# ET6801 register map
Vendor: ETMCU Inc.; File version: v0.0.1
CPU: CM7 r2p1, little endian, MPU, FPU, I-cache, D-cache, ITCM, DTCM, 4 interrupt priority bits
Registers are 32-bit, read-write, reset 0x0 unless marked. A register's access mark holds for its fields unless they carry their own. Offsets are from the block's base; [hi:lo] are bit positions.

## CAN_MISC0 — Provide an overview of the purpose and functionality of the peripheral: mttcan_misc
Base 0x40518800
Same registers: CAN_MISC1 0x40520800, CAN_MISC2 0x40528800
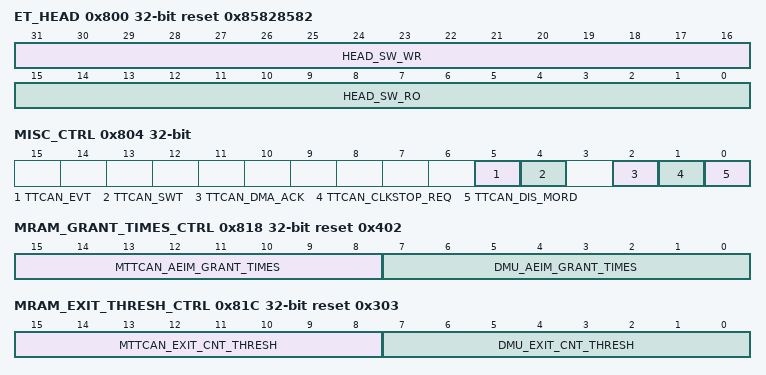
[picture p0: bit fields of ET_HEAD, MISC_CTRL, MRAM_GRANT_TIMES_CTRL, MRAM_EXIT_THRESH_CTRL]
0x800 ET_HEAD reset 0x85828582
  [31:16] HEAD_SW_WR — 软件测试读写寄存器，硬件无访问
  [15:0] HEAD_SW_RO ro — 软件只读上报寄存器，硬件无访问,FDCAN的FC的ASICII 码表示
0x804 MISC_CTRL
  [5] TTCAN_EVT — Event trigger. An edge at this port can directly trigger the transmission of a TTCAN reference message to start a communication cycle when the M_TTCAN is operated in event-synchronized time-triggered mode.
  [4] TTCAN_SWT — Stop-watch trigger An edge at this port can trigger the capturing of one of the M_TTCAN's time bases (local time, cycle time, or global time) into the stopwatch register. This enables the application software to e.g. measure the phase shift between two TTCAN networks.
  [2] TTCAN_DMA_ACK — DMA acknowledge After the transfer of the received messages has completed, the Host activates input signal m_ttcan_dma_ack. This resets m_ttcan_dma_req.
  [1] TTCAN_CLKSTOP_REQ — Clk stop request The M_TTCAN can be set into power down mode controlled by this bit.
  [0] TTCAN_DIS_MORD — Disable modifification on read controls the "disable modifification on read" function. With m_ttcan_dis_mord = '1', resetting of bit fifield ECR.CEL and bits PSR.PXE, PSR.RFDF, PSR.RBRS, PSR.RESI as well as setting of bit fifields PSR.LEC and PSR.DLEC by a read access is disabled. As long as m_ttcan_dis_mord = '1', the CPU can read out these bit fifields repeatedly without resetting/setting them.
0x808 MTTCAN_IR ro
  [31:0] TTCAN_IR — Interrupt Register flflags (IR)
0x80C MTTCAN_TTIR ro
  [18:0] TTCAN_TTIR — TT Interrupt Register flflags (TTIR)
0x810 MTTCAN_TXBRP ro
  [31:0] TTCAN_TXBRP — Tx Buffer Request Pending (TXBRP)
0x814 MTTCAN_EXTS
  [31:0] TTCAN_EXTS — external timestamp vector an external 32-bit timer for timestamp generation
0x818 MRAM_GRANT_TIMES_CTRL reset 0x402
  [15:8] MTTCAN_AEIM_GRANT_TIMES — 当M_TTCAN与DMU访问MRAM冲突时，要求mttcan完成该寄存器值次数访问后需要退出MRAM访问，将MRAM访问权释放给DMU（6002已经删除该功能，采用RR仲裁方式）
  [7:0] DMU_AEIM_GRANT_TIMES — 当DMU有访问MRAM需求，而M_TTCAN无访问需求，要求间隔该寄存器个CAN_HCLK，M_TTCAN释放 MRAM访问权后（6002已经删除该功能，采用RR仲裁方式）
0x81C MRAM_EXIT_THRESH_CTRL reset 0x303
  [15:8] MTTCAN_EXIT_CNT_THRESH — 当M_TTCAN与DMU访问MRAM冲突时，要求mttcan释放 MRAM访问权后，间隔该寄存器个CAN_HCLK才能再次请求MRAM访问权（6002已经删除该功能，采用RR仲裁方式）
  [7:0] DMU_EXIT_CNT_THRESH — 当M_TTCAN有访问MRAM需求，而DMU无访问需求，要求间隔该寄存器个CAN_HCLK，DMU释放 MRAM访问权后（6002已经删除该功能，采用RR仲裁方式）
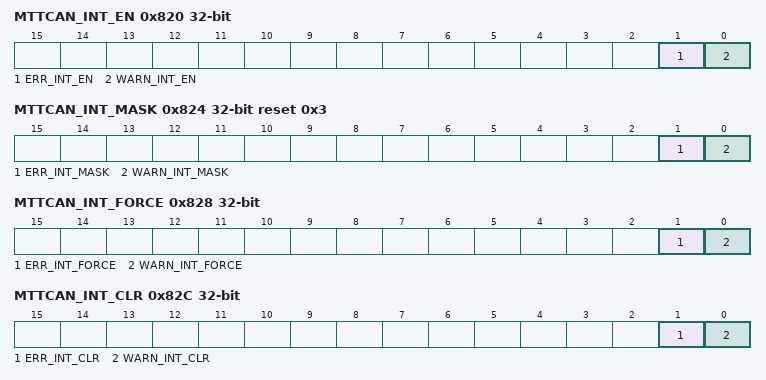
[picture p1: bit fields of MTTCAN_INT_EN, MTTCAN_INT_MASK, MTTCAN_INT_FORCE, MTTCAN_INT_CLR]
0x820 MTTCAN_INT_EN
  [1] ERR_INT_EN — Message RAM ECC fatal interrupt enable config
  [0] WARN_INT_EN — Message RAM ECC correct interrupt enable config
0x824 MTTCAN_INT_MASK reset 0x3
  [1] ERR_INT_MASK — Message RAM ECC fatal interrupt mask config
  [0] WARN_INT_MASK — Message RAM ECC correct interrupt mask config
0x828 MTTCAN_INT_FORCE
  [1] ERR_INT_FORCE — 1表示强制产生相应的测试中断，硬件自清零
  [0] WARN_INT_FORCE — 1表示强制产生相应的测试中断，硬件自清零
0x82C MTTCAN_INT_CLR
  [1] ERR_INT_CLR — 1表示清除测试中断，硬件自清零
  [0] WARN_INT_CLR — 1表示清除测试中断，硬件自清零
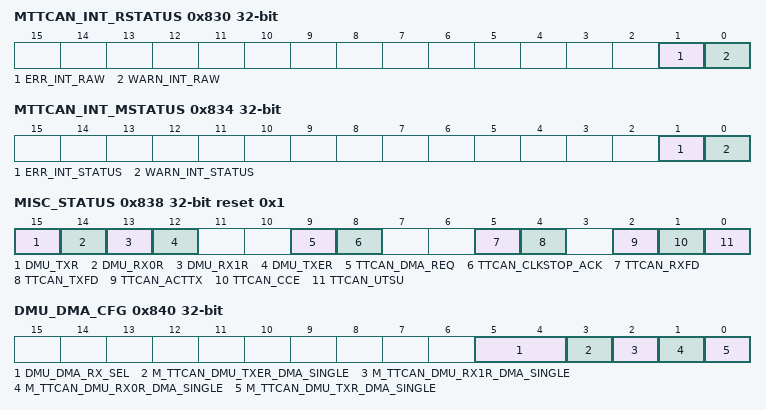
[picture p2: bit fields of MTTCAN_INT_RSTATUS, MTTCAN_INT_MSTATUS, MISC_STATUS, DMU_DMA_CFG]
0x830 MTTCAN_INT_RSTATUS ro
  [1] ERR_INT_RAW — Message RAM ECC fatal interrupt raw status
  [0] WARN_INT_RAW — Message RAM ECC correct interrupt raw status
0x834 MTTCAN_INT_MSTATUS ro
  [1] ERR_INT_STATUS — Message RAM ECC fatal interrupt masked status
  [0] WARN_INT_STATUS — Message RAM ECC correct interrupt masked status
0x838 MISC_STATUS ro reset 0x1
  [15] DMU_TXR — Request For DMA TX FIFO/Queue service
  [14] DMU_RX0R — Request For DMA RX 0 FIFO service
  [13] DMU_RX1R — Request For DMA RX 1 FIFO service
  [12] DMU_TXER — Request For DMA TX EVENT FIFO service
  [9] TTCAN_DMA_REQ — DMA request When all three debug messages A, B, C have been received in the correct order, M_TTCAN output signal m_ttcan_dma_req is activated to trigger a DMA transfer. The Message RAM words holding debug messages A, B, C will not be changed by the M_TTCAN while m_ttcan_dma_req is active
  [8] TTCAN_CLKSTOP_ACK — clock stop acknowledge When all pending transmission requests have completed, the M_TTCAN waits until bus idle state is detected. Then the M_TTCAN sets then CCCR.INIT to one to prevent any further CAN transfers. Now the M_TTCAN acknowledges that it is ready for power down by setting output signal m_ttcan_clkstop_ack to one
  [5] TTCAN_RXFD — receive fast data
  [4] TTCAN_TXFD — transmit fast data
  [2] TTCAN_ACTTX — communication state is transmitter, active when PSR.ACT = "11"
  [1] TTCAN_CCE — M_TTCAN confifiguration change enabled, active while CCCR.CCE = '1'
  [0] TTCAN_UTSU — use of TSU enabled
0x83C DMU_DMA_WAIT_TCNT reset 0xFFFFFFFF
  [31:0] DMU_DMA_WAIT_2T — 例如：Can dmu和dma交互的dmu_txr硬件请求握手适配时，当dma的req/ack握手后，需要等cfg_dmu_dma_wait_2t[7:0]个cycle后，才能向dma发起下一次传输请求； 32bit的配置中分别属于： Cfg_dmu_dma_wait_2t[7:0]:dmu_txr; Cfg_dmu_dma_wait_2t[15:8]:dmu_rx0r; Cfg_dmu_dma_wait_2t[23:16]:dmu_rx1r; Cfg_dmu_dma_wait_2t[31:24]:dmu_txer;
0x840 DMU_DMA_CFG
  [5:4] DMU_DMA_RX_SEL — 由于dma外设请求通道太少，将dmu_rx0r/dmu_rx1r/dmu_txer三个从CRAM到MRAM的搬移场景进行静态选择，同一个can只能配置上面三个中的1个dma service。 Cfg_dmu_dma_rx_sel为： 2'b00:选择dmu_rx0r； 2'b01:选择dmu_rx1r； 2'b10:选择dmu_txer； 其他：选择dmu_rx0r；
  [3] M_TTCAN_DMU_TXER_DMA_SINGLE — Dmu的dmu_txer service的dma_req_single配置寄存，软件可读写，硬件只读，用于配置是dmu_txer dma service是否请求single
  [2] M_TTCAN_DMU_RX1R_DMA_SINGLE — Dmu的dmu_rx1r service的dma_req_single配置寄存，软件可读写，硬件只读，用于配置是dmu_rx1r dma service是否请求single
  [1] M_TTCAN_DMU_RX0R_DMA_SINGLE — Dmu的dmu_rx0r service的dma_req_single配置寄存，软件可读写，硬件只读，用于配置是dmu_rx0r dma service是否请求single
  [0] M_TTCAN_DMU_TXR_DMA_SINGLE — Dmu的dmu_txr service的dma_req_single配置寄存，软件可读写，硬件只读，用于配置是dmu_txr dma service是否请求single
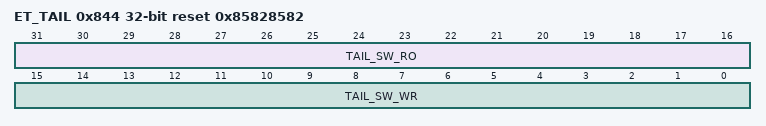
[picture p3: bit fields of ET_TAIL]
0x844 ET_TAIL reset 0x85828582
  [31:16] TAIL_SW_RO ro — 软件只读硬件上报寄存器
  [15:0] TAIL_SW_WR — 软件测试读写寄存器，硬件无访问
